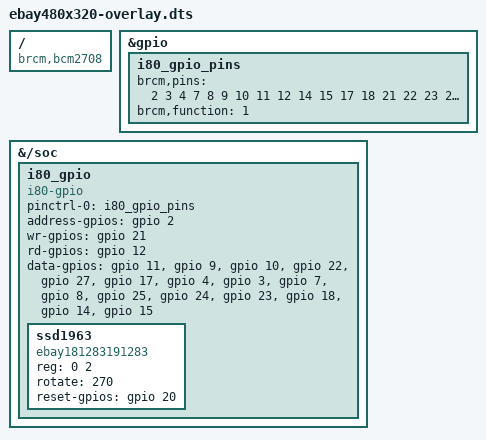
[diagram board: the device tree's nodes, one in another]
/*
 * Device Tree overlay
 *
 */

/dts-v1/;
/plugin/;

/ {
	compatible = "brcm,bcm2708";
	
	fragment@0 {
		target = <&gpio>;
		__overlay__ {
			i80_gpio_pins: i80_gpio_pins {
				brcm,pins = <2 3 4 7 8 9 10 11 12 14 15 17 18 21 22 23 24 25 27>;
				brcm,function = <1>; /* out */
			};
		};
	};

	fragment@1 {
		target-path = "/soc";
		__overlay__ {
			i80_gpio: i80_gpio {
				compatible = "i80-gpio";
				pinctrl-names = "default";
				pinctrl-0 = <&i80_gpio_pins>;
				#address-cells = <1>;
				#size-cells = <1>;

				address-gpios = <&gpio 2 0>;
				wr-gpios = <&gpio 21 0>;
				rd-gpios = <&gpio 12 0>;
				data-gpios = <&gpio 11 0>,
					     <&gpio  9 0>,
					     <&gpio 10 0>,
					     <&gpio 22 0>,
					     <&gpio 27 0>,
					     <&gpio 17 0>,
					     <&gpio  4 0>,
					     <&gpio  3 0>,
					     <&gpio  7 0>,
					     <&gpio  8 0>,
					     <&gpio 25 0>,
					     <&gpio 24 0>,
					     <&gpio 23 0>,
					     <&gpio 18 0>,
					     <&gpio 14 0>,
					     <&gpio 15 0>;

				ssd1963: ssd1963 {
					compatible = "ebay181283191283";
					reg = <0 2>; /* chip always selected */
			
					rotate = <270>;
					reset-gpios = <&gpio 20 0>;
				};
			};
		};
	};
};
